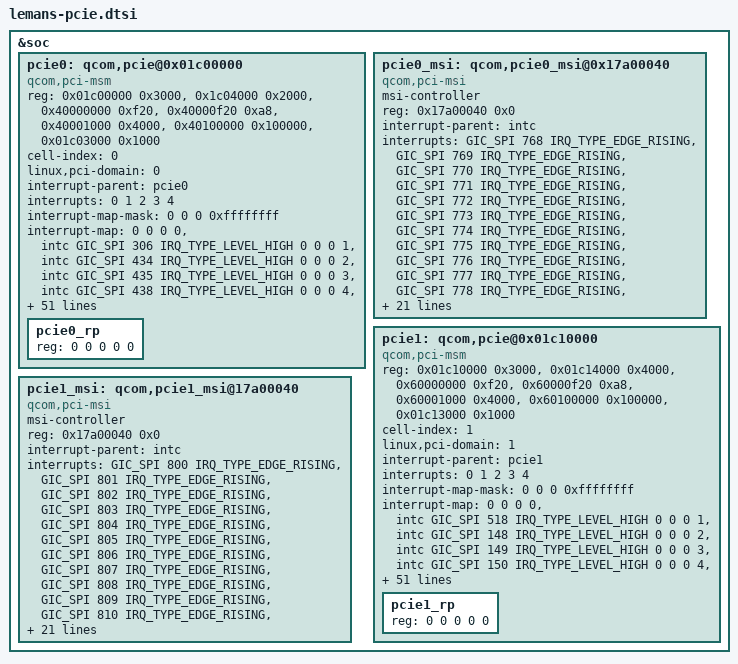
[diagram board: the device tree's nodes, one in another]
#include <dt-bindings/clock/qcom,gcc-lemans.h>
#include <dt-bindings/gpio/gpio.h>

&soc {
	pcie0: qcom,pcie@0x01c00000 {
		compatible = "qcom,pci-msm";

		reg = <0x01c00000 0x3000>,
			<0x1c04000 0x2000>,
			<0x40000000 0xf20>,
			<0x40000f20 0xa8>,
			<0x40001000 0x4000>,
			<0x40100000 0x100000>,
			<0x01c03000 0x1000>;
		reg-names = "parf", "phy", "dm_core", "elbi",
				"iatu", "conf", "mhi";

		cell-index = <0>;
		linux,pci-domain = <0>;

		#address-cells = <3>;
		#size-cells = <2>;
		ranges = <0x01000000 0x0 0x40200000 0x40200000 0x0 0x100000>,
			<0x02000000 0x0 0x40300000 0x40300000 0x0 0x1fd00000>;

		interrupt-parent = <&pcie0>;
		interrupts = <0 1 2 3 4>;
		interrupt-names = "int_global_int", "int_a", "int_b", "int_c",
				"int_d";
		#interrupt-cells = <1>;
		interrupt-map-mask = <0 0 0 0xffffffff>;
		interrupt-map = <0 0 0 0 &intc GIC_SPI 306 IRQ_TYPE_LEVEL_HIGH
				0 0 0 1 &intc GIC_SPI 434 IRQ_TYPE_LEVEL_HIGH
				0 0 0 2 &intc GIC_SPI 435 IRQ_TYPE_LEVEL_HIGH
				0 0 0 3 &intc GIC_SPI 438 IRQ_TYPE_LEVEL_HIGH
				0 0 0 4 &intc GIC_SPI 439 IRQ_TYPE_LEVEL_HIGH>;

		perst-gpio = <&tlmm 2 GPIO_ACTIVE_HIGH>;
		wake-gpio = <&tlmm 0 GPIO_ACTIVE_HIGH>;
		pinctrl-names = "default", "sleep";
		pinctrl-0 = <&pcie0_perst_default
				&pcie0_clkreq_default
				&pcie0_wake_default>;
		pinctrl-1 = <&pcie0_perst_default
				&pcie0_clkreq_sleep
				&pcie0_wake_default>;

		gdsc-vdd-supply = <&gcc_pcie_0_gdsc>;
		vreg-1p8-supply = <&L1C>;
		vreg-0p9-supply = <&L5A>;
		vreg-mx-supply = <&VDD_MXC_LEVEL>;

		qcom,vreg-1p8-voltage-level = <1200000 1200000 25800>;
		qcom,vreg-0p9-voltage-level = <880000 880000 186000>;
		qcom,vreg-mx-voltage-level = <RPMH_REGULATOR_LEVEL_MAX
						RPMH_REGULATOR_LEVEL_NOM 0>;

		qcom,bw-scale = /* Gen1 */
				<RPMH_REGULATOR_LEVEL_SVS_L1
				RPMH_REGULATOR_LEVEL_SVS_L1
				19200000
				/* Gen2 */
				RPMH_REGULATOR_LEVEL_SVS_L1
				RPMH_REGULATOR_LEVEL_SVS_L1
				19200000
				/* Gen3 */
				RPMH_REGULATOR_LEVEL_SVS_L1
				RPMH_REGULATOR_LEVEL_SVS_L1
				100000000
				/* Gen4 */
				RPMH_REGULATOR_LEVEL_NOM
				RPMH_REGULATOR_LEVEL_NOM
				100000000>;

		interconnect-names = "icc_path";
		interconnects = <&pcie_anoc MASTER_PCIE_0 &mc_virt SLAVE_EBI1>;

		clocks = <&gcc GCC_PCIE_0_PIPE_CLK>,
			<&rpmhcc RPMH_CXO_CLK>,
			<&gcc GCC_PCIE_0_AUX_CLK>,
			<&gcc GCC_PCIE_0_CFG_AHB_CLK>,
			<&gcc GCC_PCIE_0_MSTR_AXI_CLK>,
			<&gcc GCC_PCIE_0_SLV_AXI_CLK>,
			<&gcc GCC_PCIE_CLKREF_EN>,
			<&gcc GCC_PCIE_0_AUX_CLK_SRC>,
			<&gcc GCC_PCIE_0_SLV_Q2A_AXI_CLK>,
			<&gcc GCC_PCIE_0_PHY_RCHNG_CLK>,
			<&gcc GCC_PCIE_0_PHY_RCHNG_CLK_SRC>,
			<&gcc GCC_PCIE_0_PIPE_DIV_CLK_SRC>,
			<&gcc GCC_PCIE_0_PIPE_CLK_SRC>,
			<&gcc GCC_PCIE_0_PHY_AUX_CLK>,
			<&gcc GCC_PCIE_0_PIPEDIV2_CLK>,
			<&gcc GCC_PCIE_0_PHY_AUX_CLK_SRC>,
			<&pcie_0_pipe_clk>;

		clock-names = "pcie_0_pipe_clk", "pcie_0_ref_clk_src",
				"pcie_0_aux_clk", "pcie_0_cfg_ahb_clk",
				"pcie_0_mstr_axi_clk", "pcie_0_slv_axi_clk",
				"pcie_0_ldo", "pcie_0_aux_clk_src",
				"pcie_0_slv_q2a_axi_clk", "pcie_phy_refgen_clk",
				"pcie_phy_refgen_clk_src", "pcie_0_pipe_div_clk_src",
				"pcie_pipe_clk_mux", "pcie_phy_aux_clk",
				"pcie_0_pipediv2_clk", "pcie_phy_aux_clk_src",
				"pcie_pipe_clk_ext_src";

		max-clock-frequency-hz = <0>, <0>, <19200000>, <0>, <0>, <0>,
					<0>, <0>, <0>, <0>, <100000000>, <0>,
					<0>, <0>, <0>, <0>, <0>;

		resets = <&gcc GCC_PCIE_0_BCR>,
			<&gcc GCC_PCIE_0_PHY_NOCSR_COM_PHY_BCR>;
		reset-names = "pcie_0_core_reset",
				"pcie_phy_nocsr_com_phy_reset";

		dma-coherent;
		qcom,smmu-sid-base = <0x0000>;

		qcom,boot-option = <0x0>;
		qcom,aux-clk-freq = <20>; /* 19.2 MHz */
		qcom,slv-addr-space-size = <0x1fd00000>;
		qcom,ep-latency = <10>;
		qcom,core-preset = <0x77777777>;

		qcom,phy-status-offset = <0x1214>;
		qcom,phy-status-bit = <7>;
		qcom,phy-power-down-offset = <0x1240>;

		pcie0_rp: pcie0_rp {
			reg = <0 0 0 0 0>;
		};
	};

	pcie0_msi: qcom,pcie0_msi@0x17a00040 {
			compatible = "qcom,pci-msi";
			msi-controller;
			reg = <0x17a00040 0x0>;
			interrupt-parent = <&intc>;
			interrupts = <GIC_SPI 768 IRQ_TYPE_EDGE_RISING>,
				<GIC_SPI 769 IRQ_TYPE_EDGE_RISING>,
				<GIC_SPI 770 IRQ_TYPE_EDGE_RISING>,
				<GIC_SPI 771 IRQ_TYPE_EDGE_RISING>,
				<GIC_SPI 772 IRQ_TYPE_EDGE_RISING>,
				<GIC_SPI 773 IRQ_TYPE_EDGE_RISING>,
				<GIC_SPI 774 IRQ_TYPE_EDGE_RISING>,
				<GIC_SPI 775 IRQ_TYPE_EDGE_RISING>,
				<GIC_SPI 776 IRQ_TYPE_EDGE_RISING>,
				<GIC_SPI 777 IRQ_TYPE_EDGE_RISING>,
				<GIC_SPI 778 IRQ_TYPE_EDGE_RISING>,
				<GIC_SPI 779 IRQ_TYPE_EDGE_RISING>,
				<GIC_SPI 780 IRQ_TYPE_EDGE_RISING>,
				<GIC_SPI 781 IRQ_TYPE_EDGE_RISING>,
				<GIC_SPI 782 IRQ_TYPE_EDGE_RISING>,
				<GIC_SPI 783 IRQ_TYPE_EDGE_RISING>,
				<GIC_SPI 784 IRQ_TYPE_EDGE_RISING>,
				<GIC_SPI 785 IRQ_TYPE_EDGE_RISING>,
				<GIC_SPI 786 IRQ_TYPE_EDGE_RISING>,
				<GIC_SPI 787 IRQ_TYPE_EDGE_RISING>,
				<GIC_SPI 788 IRQ_TYPE_EDGE_RISING>,
				<GIC_SPI 789 IRQ_TYPE_EDGE_RISING>,
				<GIC_SPI 790 IRQ_TYPE_EDGE_RISING>,
				<GIC_SPI 791 IRQ_TYPE_EDGE_RISING>,
				<GIC_SPI 792 IRQ_TYPE_EDGE_RISING>,
				<GIC_SPI 793 IRQ_TYPE_EDGE_RISING>,
				<GIC_SPI 794 IRQ_TYPE_EDGE_RISING>,
				<GIC_SPI 795 IRQ_TYPE_EDGE_RISING>,
				<GIC_SPI 796 IRQ_TYPE_EDGE_RISING>,
				<GIC_SPI 797 IRQ_TYPE_EDGE_RISING>,
				<GIC_SPI 798 IRQ_TYPE_EDGE_RISING>,
				<GIC_SPI 799 IRQ_TYPE_EDGE_RISING>;
	};


	pcie1: qcom,pcie@0x01c10000 {
		compatible = "qcom,pci-msm";

		reg = <0x01c10000 0x3000>,
			<0x01c14000 0x4000>,
			<0x60000000 0xf20>,
			<0x60000f20 0xa8>,
			<0x60001000 0x4000>,
			<0x60100000 0x100000>,
			<0x01c13000 0x1000>;
		reg-names = "parf", "phy", "dm_core",
				"elbi", "iatu", "conf", "mhi";

		cell-index = <1>;
		linux,pci-domain = <1>;

		#address-cells = <3>;
		#size-cells = <2>;
		ranges = <0x01000000 0x0 0x60200000 0x60200000 0x0 0x100000>,
			<0x02000000 0x0  0x60300000 0x60300000 0x0 0x1fd00000>;

		interrupt-parent = <&pcie1>;
		interrupts = <0 1 2 3 4>;
		interrupt-names = "int_global_int", "int_a", "int_b", "int_c",
				"int_d";
		#interrupt-cells = <1>;
		interrupt-map-mask = <0 0 0 0xffffffff>;
		interrupt-map = <0 0 0 0 &intc GIC_SPI 518 IRQ_TYPE_LEVEL_HIGH
				0 0 0 1 &intc GIC_SPI 148 IRQ_TYPE_LEVEL_HIGH
				0 0 0 2 &intc GIC_SPI 149 IRQ_TYPE_LEVEL_HIGH
				0 0 0 3 &intc GIC_SPI 150 IRQ_TYPE_LEVEL_HIGH
				0 0 0 4 &intc GIC_SPI 151 IRQ_TYPE_LEVEL_HIGH>;

		perst-gpio = <&tlmm 4 GPIO_ACTIVE_HIGH>;
		wake-gpio = <&tlmm 5 GPIO_ACTIVE_HIGH>;
		pinctrl-names = "default", "sleep";
		pinctrl-0 = <&pcie1_perst_default
				&pcie1_clkreq_default
				&pcie1_wake_default>;
		pinctrl-1 = <&pcie1_perst_default
				&pcie1_clkreq_sleep
				&pcie1_wake_default>;

		gdsc-vdd-supply = <&gcc_pcie_1_gdsc>;
		vreg-1p8-supply = <&L1C>;
		vreg-0p9-supply = <&L5A>;
		vreg-mx-supply = <&VDD_MXC_LEVEL>;

		qcom,vreg-1p8-voltage-level = <1200000 1200000 33300>;
		qcom,vreg-0p9-voltage-level = <880000 880000 439000>;
		qcom,vreg-mx-voltage-level = <RPMH_REGULATOR_LEVEL_MAX
						RPMH_REGULATOR_LEVEL_NOM 0>;

		qcom,bw-scale = /* Gen1 */
				<RPMH_REGULATOR_LEVEL_SVS_L1
				RPMH_REGULATOR_LEVEL_SVS_L1
				19200000
				/* Gen2 */
				RPMH_REGULATOR_LEVEL_SVS_L1
				RPMH_REGULATOR_LEVEL_SVS_L1
				19200000
				/* Gen3 */
				RPMH_REGULATOR_LEVEL_SVS_L1
				RPMH_REGULATOR_LEVEL_SVS_L1
				100000000
				/* Gen4 */
				RPMH_REGULATOR_LEVEL_NOM
				RPMH_REGULATOR_LEVEL_NOM
				100000000>;

		interconnect-names = "icc_path";
		interconnects = <&pcie_anoc MASTER_PCIE_1 &mc_virt SLAVE_EBI1>;

		clocks = <&gcc GCC_PCIE_1_PIPE_CLK>,
			<&rpmhcc RPMH_CXO_CLK>,
			<&gcc GCC_PCIE_1_AUX_CLK>,
			<&gcc GCC_PCIE_1_CFG_AHB_CLK>,
			<&gcc GCC_PCIE_1_MSTR_AXI_CLK>,
			<&gcc GCC_PCIE_1_SLV_AXI_CLK>,
			<&gcc GCC_PCIE_CLKREF_EN>,
			<&gcc GCC_PCIE_1_AUX_CLK_SRC>,
			<&gcc GCC_PCIE_1_SLV_Q2A_AXI_CLK>,
			<&gcc GCC_PCIE_1_PHY_RCHNG_CLK>,
			<&gcc GCC_PCIE_1_PHY_RCHNG_CLK_SRC>,
			<&gcc GCC_PCIE_1_PIPE_DIV_CLK_SRC>,
			<&gcc GCC_PCIE_1_PIPE_CLK_SRC>,
			<&gcc GCC_PCIE_1_PHY_AUX_CLK>,
			<&gcc GCC_PCIE_1_PIPEDIV2_CLK>,
			<&gcc GCC_PCIE_1_PHY_AUX_CLK_SRC>,
			<&pcie_1_pipe_clk>;

		clock-names = "pcie_1_pipe_clk", "pcie_1_ref_clk_src",
				"pcie_1_aux_clk", "pcie_1_cfg_ahb_clk",
				"pcie_1_mstr_axi_clk", "pcie_1_slv_axi_clk",
				"pcie_1_ldo", "pcie_1_aux_clk_src",
				"pcie_1_slv_q2a_axi_clk", "pcie_phy_refgen_clk",
				"pcie_phy_refgen_clk_src", "pcie_1_pipe_div_clk_src",
				"pcie_pipe_clk_mux", "pcie_phy_aux_clk",
				"pcie_1_pipediv2_clk", "pcie_phy_aux_clk_src",
				"pcie_pipe_clk_ext_src";

		max-clock-frequency-hz = <0>, <0>, <19200000>, <0>, <0>, <0>,
					<0>, <0>, <0>, <0>, <100000000>, <0>,
					<0>, <0>, <0>, <0>, <0>;

		resets = <&gcc GCC_PCIE_1_BCR>,
			<&gcc GCC_PCIE_1_PHY_NOCSR_COM_PHY_BCR>;
		reset-names = "pcie_1_core_reset",
				"pcie_phy_nocsr_com_phy_reset";

		dma-coherent;
		qcom,smmu-sid-base = <0x0080>;

		qcom,boot-option = <0x0>;
		qcom,aux-clk-freq = <20>; /* 19.2 MHz */
		qcom,slv-addr-space-size = <0x1fd00000>;
		qcom,ep-latency = <10>;
		qcom,core-preset = <0x77777777>;

		qcom,phy-status-offset = <0x2214>;
		qcom,phy-status-bit = <7>;
		qcom,phy-power-down-offset = <0x2240>;

		pcie1_rp: pcie1_rp {
			reg = <0 0 0 0 0>;
		};
	};

	pcie1_msi: qcom,pcie1_msi@17a00040 {
		compatible = "qcom,pci-msi";
		msi-controller;
		reg = <0x17a00040 0x0>;
		interrupt-parent = <&intc>;
		interrupts = <GIC_SPI 800 IRQ_TYPE_EDGE_RISING>,
			<GIC_SPI 801 IRQ_TYPE_EDGE_RISING>,
			<GIC_SPI 802 IRQ_TYPE_EDGE_RISING>,
			<GIC_SPI 803 IRQ_TYPE_EDGE_RISING>,
			<GIC_SPI 804 IRQ_TYPE_EDGE_RISING>,
			<GIC_SPI 805 IRQ_TYPE_EDGE_RISING>,
			<GIC_SPI 806 IRQ_TYPE_EDGE_RISING>,
			<GIC_SPI 807 IRQ_TYPE_EDGE_RISING>,
			<GIC_SPI 808 IRQ_TYPE_EDGE_RISING>,
			<GIC_SPI 809 IRQ_TYPE_EDGE_RISING>,
			<GIC_SPI 810 IRQ_TYPE_EDGE_RISING>,
			<GIC_SPI 811 IRQ_TYPE_EDGE_RISING>,
			<GIC_SPI 812 IRQ_TYPE_EDGE_RISING>,
			<GIC_SPI 813 IRQ_TYPE_EDGE_RISING>,
			<GIC_SPI 814 IRQ_TYPE_EDGE_RISING>,
			<GIC_SPI 815 IRQ_TYPE_EDGE_RISING>,
			<GIC_SPI 816 IRQ_TYPE_EDGE_RISING>,
			<GIC_SPI 817 IRQ_TYPE_EDGE_RISING>,
			<GIC_SPI 818 IRQ_TYPE_EDGE_RISING>,
			<GIC_SPI 819 IRQ_TYPE_EDGE_RISING>,
			<GIC_SPI 820 IRQ_TYPE_EDGE_RISING>,
			<GIC_SPI 821 IRQ_TYPE_EDGE_RISING>,
			<GIC_SPI 822 IRQ_TYPE_EDGE_RISING>,
			<GIC_SPI 823 IRQ_TYPE_EDGE_RISING>,
			<GIC_SPI 824 IRQ_TYPE_EDGE_RISING>,
			<GIC_SPI 825 IRQ_TYPE_EDGE_RISING>,
			<GIC_SPI 826 IRQ_TYPE_EDGE_RISING>,
			<GIC_SPI 827 IRQ_TYPE_EDGE_RISING>,
			<GIC_SPI 828 IRQ_TYPE_EDGE_RISING>,
			<GIC_SPI 829 IRQ_TYPE_EDGE_RISING>,
			<GIC_SPI 830 IRQ_TYPE_EDGE_RISING>,
			<GIC_SPI 831 IRQ_TYPE_EDGE_RISING>;
	};
};

